# STM32H5E5 register map
File version: 1.0
CPU: CM33 r0p0, little endian, MPU, FPU, 4 interrupt priority bits
Registers are 32-bit, read-write, reset 0x0 unless marked. A register's access mark holds for its fields unless they carry their own. Offsets are from the block's base; [hi:lo] are bit positions; {n}, {i} and the like mark numbered series; 'fields as' and 'values as' point back to an identical list.

## GFXTIM — GFXTIM register block
Base 0x40017400
Same registers: GFXTIM_S 0x50017400
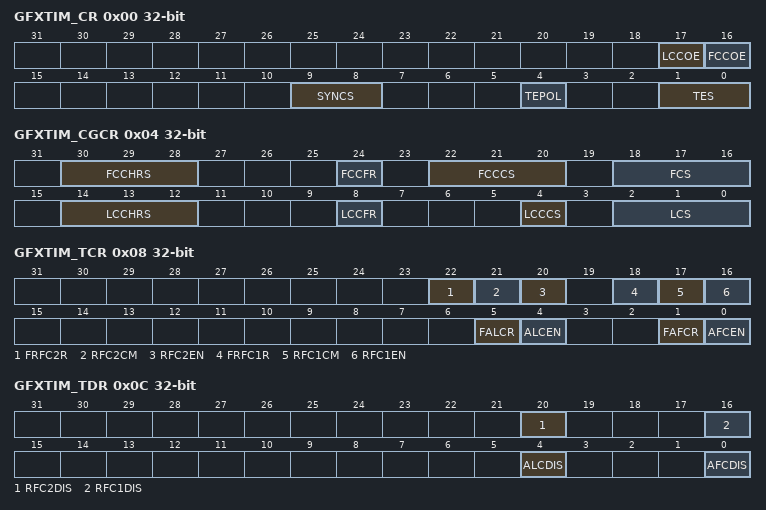
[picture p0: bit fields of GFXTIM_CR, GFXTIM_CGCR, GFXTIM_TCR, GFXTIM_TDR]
0x00 GFXTIM_CR — GFXTIM configuration register
  [17] LCCOE — Line-clock calibration output enable
    0=Line-clock output disabled; 1=Line-clock output enabled
  [16] FCCOE — Frame-clock calibration output enable
    0=Frame-clock output disabled; 1=Frame-clock output enabled
  [9:8] SYNCS — Synchronization source
    {v}=gfxtim_hsync[{v}] and gfxtim_vsync[{v}] selected (v=0..3)
  [4] TEPOL — Tearing--effect polarity
    0=Tearing effect active on rising edge; 1=Tearing effect active on falling edge
  [1:0] TES — Tearing source
    0=TE input pad selected; 1=gfxtim_ite selected; 2=HSYNC input selected by SYNCS[1:0]; 3=VSYNC input selected by SYNCS[1:0]
0x04 GFXTIM_CGCR — GFXTIM clock generator configuration register
  [30:28] FCCHRS — Frame clock counter hardware reload source
    0=No hardware reload; 1=Line- -clock counter underflow; 2=HSYNC rising edge; 3=HSYNC falling edge; 4=VSYNC rising edge; 5=VSYNC falling edge; 6=TE rising edge; 7=TE falling edge
  [24] FCCFR wo — Frame clock counter force reload
    0=No effect; 1=Frame clock counter reload forced
  [22:20] FCCCS — Frame clock counter clock source
    0=Frame clock counter disabled; 1=Line clock counter underflow; 2=HSYNC rising edge; 3=HSYNC falling edge; 4=VSYNC rising edge; 5=VSYNC falling edge; 6=TE rising edge; 7=TE falling edge
  [18:16] FCS — Frame clock source
    0=Line clock counter underflow; 1=Frame clock counter underflow; 2=HSYNC rising edge; 3=HSYNC falling edge; 4=VSYNC rising edge; 5=VSYNC falling edge; 6=TE rising edge; 7=TE falling edge
  [14:12] LCCHRS — Line clock counter hardware reload source
    0=No hardware reload; 1=Frame clock counter underflow; 2=HSYNC rising edge; 3=HSYNC falling edge; 4=VSYNC rising edge; 5=VSYNC falling edge; 6=TE rising edge; 7=TE falling edge
  [8] LCCFR wo — Line clock counter force reload
    0=No effect; 1=Line clock counter reload forced
  [4] LCCCS — Line clock counter clock source
    0=Line clock counter disabled; 1=System clock selected
  [2:0] LCS — Line clock source
    values as FCS
0x08 GFXTIM_TCR — GFXTIM timers configuration register
  [22] FRFC2R wo — Force relative frame counter 2 reload
    0=No effect; 1=Relative frame counter 2 reload forced
  [21] RFC2CM — Relative frame counter 2 continuous mode
    0=Relative frame counter 2 is one shot; 1=Relative frame counter 2 is in continuous mode
  [20] RFC2EN wo — Relative frame counter 2 enable
    0=No effect; 1=Relative frame counter 2 enabled
  [18] FRFC1R wo — Force relative frame counter 1 reload
    0=No effect; 1=Relative frame counter 1 reload forced
  [17] RFC1CM — Relative frame counter 1 continuous mode
    0=Relative frame counter 1 is one shot; 1=Relative frame counter 1 is in continuous mode
  [16] RFC1EN wo — Relative frame counter 1 enable
    0=No effect; 1=Relative frame counter enabled
  [5] FALCR wo — Force absolute line counter reset
    0=No effect; 1=Absolute line counter reset forced
  [4] ALCEN wo — Absolute line counter enable
    0=No effect; 1=Absolute line counter enabled
  [1] FAFCR wo — Force absolute frame counter reset
    0=No effect; 1=Absolute frame counter reset forced
  [0] AFCEN wo — Absolute frame counter enable
    0=No effect; 1=Absolute frame counter enabled
0x0C GFXTIM_TDR wo — GFXTIM timers disable register
  [20] RFC2DIS — Relative frame counter 2 disable
    0=No effect; 1=Relative frame counter 2 disabled
  [16] RFC1DIS — Relative frame counter 1 disable
    0=No effect; 1=Relative frame counter 1 disabled
  [4] ALCDIS — Absolute line counter disable
    0=No effect; 1=Absolute line counter disabled
  [0] AFCDIS — Absolute frame counter disable
    0=No effect; 1=Absolute frame counter disabled
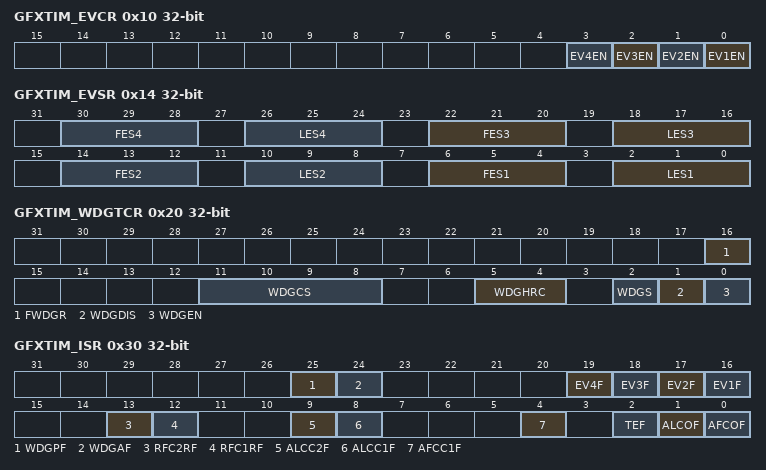
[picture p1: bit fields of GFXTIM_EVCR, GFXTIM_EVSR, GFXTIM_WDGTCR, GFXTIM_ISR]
0x10 GFXTIM_EVCR — GFXTIM events control register
  [n-1] EV{n}EN (n=1..4) — Event {n} enable
    0=Event {n} generation disabled; 1=Event {n} generation enabled
0x14 GFXTIM_EVSR — GFXTIM events selection register
  [8n-2:8n-4] FES{n} (n=1..4) — Frame-event selection {n}
    0=No frame event; 1=Absolute frame counter overflow; 2=Absolute frame counter compare; 4=Relative frame counter 1 reload; 5=Relative frame counter 2 reload
  [8n-6:8n-8] LES{n} (n=1..4) — Line-event selection {n}
    0=No line event; 1=Absolute line counter overflow; 2=Tearing effect; 4=Absolute line counter 1 compare; 5=Absolute line counter 2 compare
0x20 GFXTIM_WDGTCR — GFXTIM watchdog timer configuration register
  [16] FWDGR wo — Force watchdog reload
    0=nNo effect; 1=Graphic watchdog reload forced
  [11:8] WDGCS — Watchdog clock source
    0=Line clock; 1=Frame clock; 2=HSYNC rising edge; 3=HSYNC falling edge; 4=VSYNC rising edge; 5=VSYNC falling edge; 6=TE rising edge; 7=TE falling edge; {v}=Event {v-7} (v=8..11)
  [5:4] WDGHRC — Watchdog hardware reload configuration
    0=Watchdog hardware reload disabled; 1=Watchdog reloaded a rising edge of gfxtim_wrld; 2=Watchdog reloaded a falling edge of gfxtim_wrld
  [2] WDGS ro — Watchdog status
    0=Graphic watchdog disabled; 1=Graphic watchdog enabled
  [1] WDGDIS wo — Watchdog disable
    0=No effect; 1=Graphic watchdog disabled
  [0] WDGEN wo — Watchdog enable
    0=No effect; 1=Graphic watchdog enabled
0x30 GFXTIM_ISR ro — GFXTIM interrupt status register
  [25] WDGPF — Watchdog pre-alarm flag
    0=No graphic watchdog pre-alarm occurred; 1=A graphic watchdog pre-alarm occurred
  [24] WDGAF — Watchdog alarm flag
    0=No graphic watchdog alarm occurred; 1=A graphic watchdog alarm occurred
  [19] EV4F — Event 4 flag
    0=No complex event 4 occurred; 1=A complex event 4 occurred
  [18] EV3F — Event 3 flag
    0=No complex event 3 occurred; 1=A complex event 3 occurred
  [17] EV2F — Event 2 flag
    0=No complex event 2 occurred; 1=A complex event 2 occurred
  [16] EV1F — Event 1 flag
    0=No complex event 1 occurred; 1=Complex event 1 occurred
  [13] RFC2RF — Relative frame counter 2 reload flag
    0=No reload occurred on relative frame counter 2; 1=A reload on relative frame counter 2 occurred
  [12] RFC1RF — Relative frame counter 1 reload flag
    0=No reload occurred on relative frame counter 1; 1=A reload on relative frame counter 1 occurred
  [9] ALCC2F — Absolute line counter compare 2 flag
    0=No match occurred on compare 2 of the absolute line counter; 1=A match on compare 2 of the absolute line counter occurred
  [8] ALCC1F — Absolute line counter compare 1 flag
    0=No match occurred on compare 1 of the absolute line counter; 1=A match on compare 1 of the absolute line counter occurred
  [4] AFCC1F — Absolute frame counter compare 1 flag
    0=No match occurred on compare 1 of the absolute frame counter; 1=A match on compare 1 of the absolute frame counter occurred
  [2] TEF — Tearing-effect flag
    0=No tearing effect occurred; 1=A tearing effect occurred
  [1] ALCOF — Absolute line counter overflow flag
    0=No overflow occurred on the absolute line counter; 1=A overflow on the absolute line counter occurred
  [0] AFCOF — absolute frame counter overflow flag
    0=No overflow occurred on the absolute frame counter; 1=An overflow on the absolute frame counter occurred
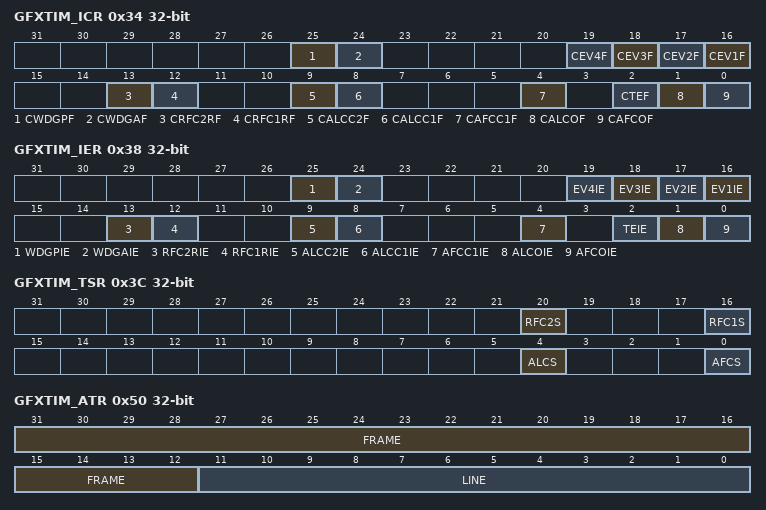
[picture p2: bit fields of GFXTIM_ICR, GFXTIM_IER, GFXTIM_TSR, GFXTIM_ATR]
0x34 GFXTIM_ICR wo — GFXTIM interrupt clear register
  [25] CWDGPF — Clear watchdog pre-alarm flag
    0=No effect; 1=WDGPF cleared
  [24] CWDGAF — Clear watchdog alarm flag
    0=No effect; 1=WDGAF cleared
  [n+15] CEV{n}F (n=1..4) — Clear event {n} flag
    0=No effect; 1=EV{n}F cleared
  [13] CRFC2RF — Clear relative frame counter 2 reload flag
    0=No effect; 1=RFC2RF cleared
  [12] CRFC1RF — Clear relative frame counter 1 reload flag
    0=No effect; 1=RFC1RF cleared
  [9] CALCC2F — Clear absolute line counter compare 2 flag
    0=No effect; 1=ALCC2F cleared
  [8] CALCC1F — Clear absolute line counter compare 1 flag
    0=No effect; 1=ALCC1F cleared
  [4] CAFCC1F — Clear absolute frame counter compare 1 flag
    0=No effect; 1=AFCC1F cleared
  [2] CTEF — Clear tearing-effect flag
    0=No effect; 1=TEF cleared
  [1] CALCOF — Clear absolute line counter overflow flag
    0=No effect; 1=ALCOF cleared
  [0] CAFCOF — Clear absolute frame counter overflow flag
    0=No effect; 1=AFCOF cleared
0x38 GFXTIM_IER — GFXTIM interrupt enable register
  [25] WDGPIE — Watchdog pre-alarm interrupt enable
    0=Watchdog pre-alarm interrupt disabled; 1=Watchdog pre-alarm interrupt enabled
  [24] WDGAIE — Watchdog alarm interrupt enable
    0=Watchdog alarm interrupt disabled; 1=Watchdog alarm interrupt enabled
  [n+15] EV{n}IE (n=1..4) — Event {n} interrupt enable
    0=Event {n} interrupt disabled; 1=Event {n} interrupt enabled
  [13] RFC2RIE — Relative frame counter 2 reload interrupt enable
    0=Relative frame counter 2 reload interrupt disabled; 1=Relative frame counter 2 reload interrupt enabled
  [12] RFC1RIE — Relative frame counter 1 reload interrupt enable
    0=Relative frame counter 1 reload interrupt disabled; 1=Relative frame counter 1 reload interrupt enabled
  [9] ALCC2IE — Absolute line counter compare 2 interrupt enable
    0=Absolute line counter compare 2 interrupt disabled; 1=Absolute line counter compare 2 interrupt enabled
  [8] ALCC1IE — Absolute line counter compare 1 interrupt enable
    0=Absolute line counter compare 1 interrupt disabled; 1=Absolute line counter compare 1 interrupt enabled
  [4] AFCC1IE — Absolute frame counter compare 1 interrupt enable
    0=Absolute frame counter compare 1 interrupt disabled; 1=Absolute frame counter compare 1 interrupt enabled
  [2] TEIE — Tearing-effect interrupt enable
    0=Tearing-effect interrupt disabled; 1=Tearing-effect interrupt enabled
  [1] ALCOIE — Absolute line counter overflow interrupt enable
    0=Absolute line counter overflow interrupt disabled; 1=Absolute line counter overflow interrupt enabled
  [0] AFCOIE — Absolute frame counter overflow interrupt enable
    0=Absolute frame counter overflow interrupt disabled; 1=Absolute frame counter overflow interrupt enabled
0x3C GFXTIM_TSR ro — GFXTIM timers status register
  [20] RFC2S — Relative frame counter 2 status
    0=Relative frame counter 2 disabled; 1=Relative frame counter 2 enabled
  [16] RFC1S — Relative frame counter 1 status
    0=Relative frame counter 1 disabled; 1=Relative frame counter 1 enabled
  [4] ALCS — Absolute line counter status
    0=Absolute line counter disabled; 1=Absolute line counter enabled
  [0] AFCS — Absolute frame counter status
    0=Absolute frame counter disabled; 1=Absolute frame counter enabled
0x40 GFXTIM_LCCRR — GFXTIM line clock counter reload register
  [21:0] RELOAD — Reload value
0x44 GFXTIM_FCCRR — GFXTIM frame clock counter reload register
  [11:0] RELOAD — Reload value
0x50 GFXTIM_ATR ro — GFXTIM absolute time register
  [31:12] FRAME — Fame number
  [11:0] LINE — Line number
0x54 GFXTIM_AFCR — GFXTIM absolute frame counter register
  [19:0] FRAME — Frame number
0x58 GFXTIM_ALCR — GFXTIM absolute line counter register
  [11:0] LINE — Line number
0x60 GFXTIM_AFCC1R — GFXTIM absolute frame counter compare 1 register
  [19:0] FRAME — Frame number
0x70 GFXTIM_ALCC1R — GFXTIM absolute line counter compare 1 register
  [11:0] LINE — Line number
0x74 GFXTIM_ALCC2R — GFXTIM absolute line counter compare 2 register
  [11:0] LINE — Line number
0x80 GFXTIM_RFC1R ro — GFXTIM relative frame counter 1 register
  [11:0] FRAME — Frame number
0x84 GFXTIM_RFC1RR — GFXTIM relative frame counter 1 reload register
  [11:0] FRAME — Frame reload value
0x88 GFXTIM_RFC2R ro — GFXTIM relative frame counter 2 register
  [11:0] FRAME — Frame number
0x8C GFXTIM_RFC2RR — GFXTIM relative frame counter 2 reload register
  [11:0] FRAME — Frame reload value
0xA0 GFXTIM_WDGCR ro — GFXTIM watchdog counter register
  [15:0] VALUE
0xA4 GFXTIM_WDGRR — GFXTIM watchdog reload register
  [15:0] RELOAD — Reload value
0xA8 GFXTIM_WDGPAR — GFXTIM watchdog pre-alarm register
  [15:0] PREALARM — Pre-alarm value

## Notices in the file
Copyright (c) 2025 STMicroelectronics.
SPDX-License-Identifier: Apache-2.0
Licensed under the Apache License, Version 2.0 (the "License");
you may not use this file except in compliance with the License.
You may obtain a copy of the License at
http://www.apache.org/licenses/LICENSE-2.0
Unless required by applicable law or agreed to in writing, software
distributed under the License is distributed on an "AS IS" BASIS,
WITHOUT WARRANTIES OR CONDITIONS OF ANY KIND, either express or implied.
See the License for the specific language governing permissions and
limitations under the License.
